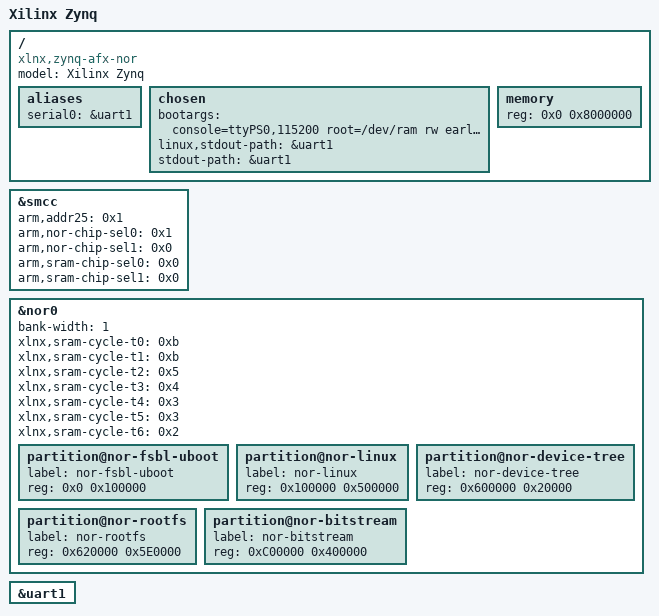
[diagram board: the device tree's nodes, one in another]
/*
 * Device Tree Generator version: 1.1
 *
 * (C) Copyright 2007-2013 Xilinx, Inc.
 * (C) Copyright 2007-2013 Michal Simek
 * (C) Copyright 2007-2012 PetaLogix Qld Pty Ltd
 *
 * Michal SIMEK <monstr@monstr.eu>
 *
 * CAUTION: This file is automatically generated by libgen.
 * Version: Xilinx EDK 14.5 EDK_P.58f
 *
 */
/dts-v1/;
/include/ "zynq-7000.dtsi"

/ {
	compatible = "xlnx,zynq-afx-nor", "xlnx,zynq-7000";
	model = "Xilinx Zynq";

	aliases {
		serial0 = &uart1;
	};

	chosen {
		bootargs = "console=ttyPS0,115200 root=/dev/ram rw earlyprintk";
		linux,stdout-path = &uart1;
		stdout-path = &uart1;
	};

	memory {
		device_type = "memory";
		reg = <0x0 0x8000000>;
	};
};

&smcc {
	status = "okay";
	arm,addr25 = <0x1>;
	arm,nor-chip-sel0 = <0x1>;
	arm,nor-chip-sel1 = <0x0>;
	arm,sram-chip-sel0 = <0x0>;
	arm,sram-chip-sel1 = <0x0>;
};

&nor0 {
	status = "okay";
	bank-width = <1>;
	xlnx,sram-cycle-t0 = <0xb>;
	xlnx,sram-cycle-t1 = <0xb>;
	xlnx,sram-cycle-t2 = <0x5>;
	xlnx,sram-cycle-t3 = <0x4>;
	xlnx,sram-cycle-t4 = <0x3>;
	xlnx,sram-cycle-t5 = <0x3>;
	xlnx,sram-cycle-t6 = <0x2>;
	partition@nor-fsbl-uboot {
		label = "nor-fsbl-uboot";
		reg = <0x0 0x100000>;
	};
	partition@nor-linux {
		label = "nor-linux";
		reg = <0x100000 0x500000>;
	};
	partition@nor-device-tree {
		label = "nor-device-tree";
		reg = <0x600000 0x20000>;
	};
	partition@nor-rootfs {
		label = "nor-rootfs";
		reg = <0x620000 0x5E0000>;
	};
	partition@nor-bitstream {
		label = "nor-bitstream";
		reg = <0xC00000 0x400000>;
	};
};

&uart1 {
	status = "okay";
};
